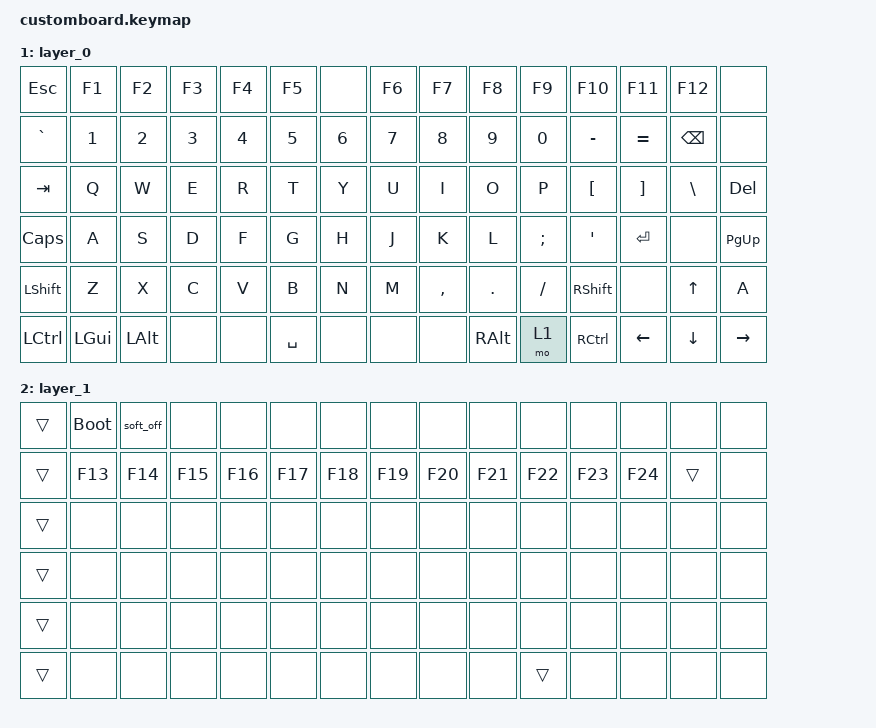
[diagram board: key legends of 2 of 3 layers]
/*
 * Copyright (c) 2022 The ZMK Contributors
 *
 * SPDX-License-Identifier: MIT
 */

#include <behaviors.dtsi>
#include <dt-bindings/zmk/keys.h>
#include <dt-bindings/zmk/bt.h>

&soft_off {
    hold-time-ms = <5000>;
};


/ {
    keymap {
        compatible = "zmk,keymap";

        encoder {
            compatible = "zmk,encoders";
            encoder-0 {
            bindings = <&inc_dec_kp C_VOL_UP C_VOL_DN>;
            };
        };


        button {
            gpios = <&gpio0 9 (GPIO_ACTIVE_LOW | GPIO_PULL_UP)>;
            label = "Encoder Button";
            bindings = <&kp ENTER>;

        };


        layer_0 {
            bindings = <
                // ROW 0: Connected to &gpio0 17 (P0.17)
                &kp ESC       &kp F1    &kp F2    &kp F3    &kp F4    &kp F5     &none      &kp F6    &kp F7    &kp F8    &kp F9    &kp F10   &kp F11   &kp F12   &none     // COL0-COL14 (15 positions)

                // ROW 1: Connected to &gpio0 20 (P0.20)
                &kp GRAVE     &kp N1    &kp N2    &kp N3    &kp N4    &kp N5     &kp N6     &kp N7    &kp N8    &kp N9    &kp N0    &kp MINUS &kp EQUAL &kp BSPC  &none     // COL0-COL14 (15 positions)

                // ROW 2: Connected to &gpio0 22 (P0.22)
                &kp TAB       &kp Q     &kp W     &kp E     &kp R     &kp T      &kp Y      &kp U     &kp I     &kp O     &kp P     &kp LBKT  &kp RBKT  &kp BSLH  &kp DEL   // COL0-COL14 (15 positions)

                // ROW 3: Connected to &gpio0 24 (P0.24)
                &kp CAPS      &kp A     &kp S     &kp D     &kp F     &kp G      &kp H      &kp J     &kp K     &kp L     &kp SEMI  &kp SQT   &kp ENTER &none     &kp PG_UP     // COL0-COL14 (15 positions)

                // ROW 4: Connected to &gpio1 0 (P1.00)
                &kp LSHFT     &kp Z     &kp X     &kp C     &kp V     &kp B      &kp N      &kp M     &kp COMMA &kp DOT   &kp SLASH &kp RSHFT &none     &kp UP    &kp A      // COL0-COL14 (15 positions)

                // ROW 5: Connected to &pca9555 15 (PCA9555 P1.7)
                &kp LCTRL     &kp LGUI  &kp LALT  &none     &none     &kp SPACE  &none      &none     &none     &kp RALT  &mo 1     &kp RCTRL &kp LEFT  &kp DOWN  &kp RIGHT     // COL0-COL14 (15 positions)
            >;
        };

        layer_1 {
            bindings = <
                &trans     &bootloader &soft_off   &none      &none     &none     &none      &none     &none     &none     &none     &none     &none     &none     &none     // row 0
                &trans     &kp F13     &kp F14     &kp F15    &kp F16   &kp F17   &kp F18    &kp F19   &kp F20   &kp F21   &kp F22   &kp F23   &kp F24   &trans    &none     // row 1
                &trans     &none       &none       &none      &none     &none     &none      &none     &none     &none     &none     &none     &none     &none     &none     // row 2
                &trans     &none       &none       &none      &none     &none     &none      &none     &none     &none     &none     &none     &none     &none     &none     // row 3
                &trans     &none       &none       &none      &none     &none     &none      &none     &none     &none     &none     &none     &none     &none     &none     // row 4
                &trans     &none       &none       &none      &none     &none     &none      &none     &none     &none     &trans    &none     &none     &none     &none     // row 5
            >;
        };
    };
};

